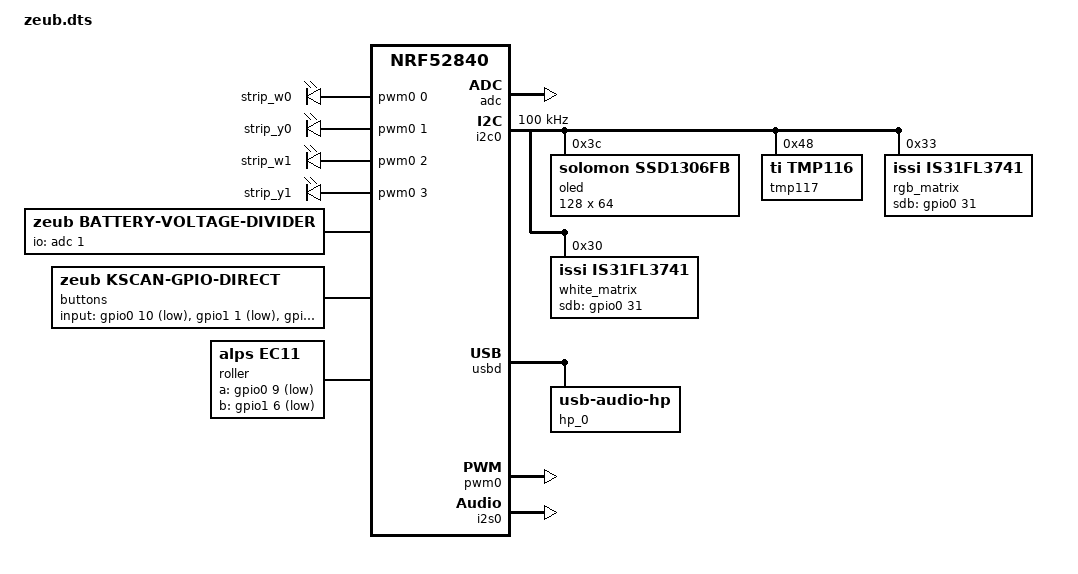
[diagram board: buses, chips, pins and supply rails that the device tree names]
/dts-v1/;
#include <nordic/nrf52840_qiaa.dtsi>

#include <dt-bindings/led/led.h>
#include <dt-bindings/zeub/is31fl3741_transform.h>
#include <dt-bindings/pwm/pwm.h>
#include "zeub-pinctrl.dtsi"

 / {
	chosen {
		zephyr,bt-mon-uart = &uart0;
		zephyr,bt-c2h-uart = &uart0;
		zephyr,sram = &sram0;
		zephyr,flash = &flash0;
		zephyr,code-partition = &flash_code_raw;
        zephyr,console = &cdc_dev;
        zephyr,display = &oled;
	};

    led_strip: led_strip {
        compatible = "pwm-leds";
        strip_w0 {
            pwms = <&pwm0 0 100000 0>;
        };
        strip_y0 {
            pwms = <&pwm0 1 100000 0>;
        };
        strip_w1 {
            pwms = <&pwm0 2 100000 0>;
        };
        strip_y1 {
            pwms = <&pwm0 3 100000 0>;
        };
    };

    bat {
        compatible = "zeub,battery-voltage-divider";
        io-channels = <&adc 1>;
        output-ohms = <1>;
        full-ohms = <(1 + 1)>;
    };

    buttons: kscan {
        compatible = "zeub,kscan-gpio-direct";
        status = "okay";
        input-gpios
			= <&gpio0 10 (GPIO_PULL_UP | GPIO_ACTIVE_LOW)>      // Encoder push button
			, <&gpio1  1 (GPIO_PULL_UP | GPIO_ACTIVE_LOW)>      // 5 way select up/A
			, <&gpio1 10 (GPIO_PULL_UP | GPIO_ACTIVE_LOW)>      // 5 way select down/D
			, <&gpio1  4 (GPIO_PULL_UP | GPIO_ACTIVE_LOW)>      // 5 way select left/C
			, <&gpio1 13 (GPIO_PULL_UP | GPIO_ACTIVE_LOW)>      // 5 way select right/B
			, <&gpio1  2 (GPIO_PULL_UP | GPIO_ACTIVE_LOW)>      // 5 way select center/E
            ;
    };

	roller: roller {
		compatible = "alps,ec11";
		status = "okay";
		a-gpios = <&gpio0 9 (GPIO_PULL_UP | GPIO_ACTIVE_LOW)>;
		b-gpios = <&gpio1 6 (GPIO_PULL_UP | GPIO_ACTIVE_LOW)>;
		resolution = <4>;
	};
};

&adc {
	status = "okay";
};

&gpiote {
	status = "okay";
};

&gpio0 {
	status = "okay";
};

&gpio1 {
	status = "okay";
};

/* &spi0 { */
/*     compatible = "nordic,nrf-spim"; */
/*     /1* status = "okay"; *1/ */
/*     sck-pin = <19>; */
/*     mosi-pin = <21>; */
/*     miso-pin = <23>; */
/* }; */

&i2c0 {
    compatible = "nordic,nrf-twi";
    status = "okay";
    pinctrl-0 = <&i2c0_def>;
    pinctrl-names = "default";
    clock-frequency = <I2C_BITRATE_STANDARD>;
    oled: ssd1306@3c {
        compatible = "solomon,ssd1306fb";
        status = "okay";
        reg = <0x3c>;
        width = <128>;
        height = <64>;
        segment-offset = <0>;
        page-offset = <0>;
        display-offset = <0>;
        multiplex-ratio = <63>;
        com-invdir;
        segment-remap;
        prechargep = <0x22>;
    };

    tmp117: tmp117@48 {
        compatible = "ti,tmp116";
        status = "okay";
        reg = <0x48>;
    };

	rgb_matrix: is31fl3741@33 {
		compatible = "issi,is31fl3741";
        status = "okay";
		reg = <0x33>;
		r-ext = <10>;
		led-max-current = <1>;
		sdb-gpios = <&gpio0 31 (GPIO_ACTIVE_HIGH | GPIO_PULL_DOWN)>;
		chain-length = <192>;
        red-scaling = <255>;
        green-scaling = <180>;
        blue-scaling = <200>;
        gamma = <0 1 2 3 4 5 6 7 8 9 10 11 12 13 14 15 16 17 18 19 20 21 22 23 24 25 26 27 28 29 30 31 32 33 34 35 36 37 38 39 40 41 42 43 44 45 46 47 48 49 50 51 52 53 54 55 56 57 58 59 60 61 62 63 64 65 66 67 68 69 70 71 72 73 74 75 76 77 78 79 80 81 82 83 84 85 86 87 88 89 90 91 92 93 94 95 96 97 98 99 100 101 102 103 104 105 106 107 108 109 110 111 112 113 114 115 116 117 118 119 120 121 122 123 124 125 126 127 128 129 130 131 132 133 134 135 136 137 138 139 140 141 142 143 144 145 146 147 148 149 150 151 152 153 154 155 156 157 158 159 160 161 162 163 164 165 166 167 168 169 170 171 172 173 174 175 176 177 178 179 180 181 182 183 184 185 186 187 188 189 190 191 192 193 194 195 196 197 198 199 200 201 202 203 204 205 206 207 208 209 210 211 212 213 214 215 216 217 218 219 220 221 222 223 224 225 226 227 228 229 230 231 232 233 234 235 236 237 238 239 240 241 242 243 244 245 246 247 248 249 250 251 252 253 254 255>;

#define PIX(c, r, g, b) RGB(SW(c), CS(r), CS(g), CS(b))
		map = <
            PIX(8, 17, 16, 15) PIX(8, 14, 13, 12) PIX(8, 11, 10, 9)  PIX(8, 8, 7, 6)
            PIX(8, 39, 38, 37) PIX(8, 36, 35, 34) PIX(8, 33, 32, 31) PIX(8, 30, 29, 28)
            PIX(7, 17, 16, 15) PIX(7, 14, 13, 12) PIX(7, 11, 10, 9)  PIX(7, 8, 7, 6)
            PIX(7, 39, 38, 37) PIX(7, 36, 35, 34) PIX(7, 33, 32, 31) PIX(7, 30, 29, 28)
            PIX(6, 17, 16, 15) PIX(6, 14, 13, 12) PIX(6, 11, 10, 9)  PIX(6, 8, 7, 6)
            PIX(6, 39, 38, 37) PIX(6, 36, 35, 34) PIX(6, 33, 32, 31) PIX(6, 30, 29, 28)
            PIX(5, 17, 16, 15) PIX(5, 14, 13, 12) PIX(5, 11, 10, 9)  PIX(5, 8, 7, 6)
            PIX(5, 39, 38, 37) PIX(5, 36, 35, 34) PIX(5, 33, 32, 31) PIX(5, 30, 29, 28)
            PIX(4, 17, 16, 15) PIX(4, 14, 13, 12) PIX(4, 11, 10, 9)  PIX(4, 8, 7, 6)
            PIX(4, 39, 38, 37) PIX(4, 36, 35, 34) PIX(4, 33, 32, 31) PIX(4, 30, 29, 28)
            PIX(3, 17, 16, 15) PIX(3, 14, 13, 12) PIX(3, 11, 10, 9)  PIX(3, 8, 7, 6)
            PIX(3, 39, 38, 37) PIX(3, 36, 35, 34) PIX(3, 33, 32, 31) PIX(3, 30, 29, 28)
            PIX(2, 17, 16, 15) PIX(2, 14, 13, 12) PIX(2, 11, 10, 9)  PIX(2, 8, 7, 6)
            PIX(2, 39, 38, 37) PIX(2, 36, 35, 34) PIX(2, 33, 32, 31) PIX(2, 30, 29, 28)
            PIX(1, 17, 16, 15) PIX(1, 14, 13, 12) PIX(1, 11, 10, 9)  PIX(1, 8, 7, 6)
            PIX(1, 39, 38, 37) PIX(1, 36, 35, 34) PIX(1, 33, 32, 31) PIX(1, 30, 29, 28)
            >;
    };

	white_matrix: is31fl3741@30 {
		compatible = "issi,is31fl3741";
        status = "okay";
		reg = <0x30>;
		r-ext = <10>;
		led-max-current = <1>;
		sdb-gpios = <&gpio0 31 (GPIO_ACTIVE_HIGH | GPIO_PULL_DOWN)>;
		chain-length = <256>;
        red-scaling = <255>;
        green-scaling = <255>;
        blue-scaling = <255>;
        gamma = <0 1 2 3 4 5 6 7 8 9 10 11 12 13 14 15 16 17 18 19 20 21 22 23 24 25 26 27 28 29 30 31 32 33 34 35 36 37 38 39 40 41 42 43 44 45 46 47 48 49 50 51 52 53 54 55 56 57 58 59 60 61 62 63 64 65 66 67 68 69 70 71 72 73 74 75 76 77 78 79 80 81 82 83 84 85 86 87 88 89 90 91 92 93 94 95 96 97 98 99 100 101 102 103 104 105 106 107 108 109 110 111 112 113 114 115 116 117 118 119 120 121 122 123 124 125 126 127 128 129 130 131 132 133 134 135 136 137 138 139 140 141 142 143 144 145 146 147 148 149 150 151 152 153 154 155 156 157 158 159 160 161 162 163 164 165 166 167 168 169 170 171 172 173 174 175 176 177 178 179 180 181 182 183 184 185 186 187 188 189 190 191 192 193 194 195 196 197 198 199 200 201 202 203 204 205 206 207 208 209 210 211 212 213 214 215 216 217 218 219 220 221 222 223 224 225 226 227 228 229 230 231 232 233 234 235 236 237 238 239 240 241 242 243 244 245 246 247 248 249 250 251 252 253 254 255>;

#define PIX16(r, c1, c2, c3, c4, c5, c6, c7, c8 , c9, c10, c11, c12, c13, c14, c15, c16) \
        PIXEL(SW(r) + CS(c1)) PIXEL(SW(r) + CS(c2)) PIXEL(SW(r) + CS(c3)) PIXEL(SW(r) + CS(c4)) \
        PIXEL(SW(r) + CS(c5)) PIXEL(SW(r) + CS(c6)) PIXEL(SW(r) + CS(c7)) PIXEL(SW(r) + CS(c8)) \
        PIXEL(SW(r) + CS(c9)) PIXEL(SW(r) + CS(c10)) PIXEL(SW(r) + CS(c11)) PIXEL(SW(r) + CS(c12)) \
        PIXEL(SW(r) + CS(c13)) PIXEL(SW(r) + CS(c14)) PIXEL(SW(r) + CS(c15)) PIXEL(SW(r) + CS(c16))
		map = <
            PIX16(1, 16, 15, 14, 13, 12, 11, 10, 9, 8, 7, 6, 5, 4, 3, 2, 1)
            PIX16(1, 39, 38, 37, 36, 35, 34, 33, 32, 31, 30, 29, 28, 27, 26, 25, 24)
            PIX16(2, 16, 15, 14, 13, 12, 11, 10, 9, 8, 7, 6, 5, 4, 3, 2, 1)
            PIX16(2, 39, 38, 37, 36, 35, 34, 33, 32, 31, 30, 29, 28, 27, 26, 25, 24)
            PIX16(3, 16, 15, 14, 13, 12, 11, 10, 9, 8, 7, 6, 5, 4, 3, 2, 1)
            PIX16(3, 39, 38, 37, 36, 35, 34, 33, 32, 31, 30, 29, 28, 27, 26, 25, 24)
            PIX16(4, 16, 15, 14, 13, 12, 11, 10, 9, 8, 7, 6, 5, 4, 3, 2, 1)
            PIX16(4, 39, 38, 37, 36, 35, 34, 33, 32, 31, 30, 29, 28, 27, 26, 25, 24)
            PIX16(5, 16, 15, 14, 13, 12, 11, 10, 9, 8, 7, 6, 5, 4, 3, 2, 1)
            PIX16(5, 39, 38, 37, 36, 35, 34, 33, 32, 31, 30, 29, 28, 27, 26, 25, 24)
            PIX16(6, 16, 15, 14, 13, 12, 11, 10, 9, 8, 7, 6, 5, 4, 3, 2, 1)
            PIX16(6, 39, 38, 37, 36, 35, 34, 33, 32, 31, 30, 29, 28, 27, 26, 25, 24)
            PIX16(7, 16, 15, 14, 13, 12, 11, 10, 9, 8, 7, 6, 5, 4, 3, 2, 1)
            PIX16(7, 39, 38, 37, 36, 35, 34, 33, 32, 31, 30, 29, 28, 27, 26, 25, 24)
            PIX16(8, 16, 15, 14, 13, 12, 11, 10, 9, 8, 7, 6, 5, 4, 3, 2, 1)
            PIX16(8, 39, 38, 37, 36, 35, 34, 33, 32, 31, 30, 29, 28, 27, 26, 25, 24)
            >;
    };
};

&spi1 { status = "disabled"; };

&flash0 {
	/*
	 * For more information, see:
	 * http://docs.zephyrproject.org/latest/devices/dts/flash_partitions.html
	 */
	my-partitions {
		compatible = "fixed-partitions";
		#address-cells = <1>;
		#size-cells = <1>;

		flash_sd: partition_sd@0 {
			label = "softdevice";
			reg = <0x00000000 0x00026000>;
		};
		flash_mbr: partition@0 {
			label = "mbr";
			reg = <0x00000000 0x00001000>;
		};
		flash_code_soft: partition@26000 {
			label = "code_partition_softdevice";
			reg = <0x00026000 0x000c6000>;
		};
		flash_code: partition@1000 {
			label = "code_partition";
			reg = <0x00001000 0x000eb000>;
		};
		flash_code_raw: partition_raw@0 {
			label = "raw_code_partition";
			reg = <0x00000000 0x000ec000>;
		};

		/*
		 * The flash starting at 0x000ec000 and ending at
		 * 0x000f3fff is reserved for use by the application.
		 */

		/*
		 * Storage partition will be used by FCB/LittleFS/NVS
		 * if enabled.
		 */
		storage_partition: partition@ec000 {
			label = "storage";
			reg = <0x000ec000 0x00008000>;
		};

		flash_boot: partition@f4000 {
			label = "adafruit_boot";
			reg = <0x000f4000 0x0000c000>;
		};
	};
};

zephyr_udc0: &usbd {
	compatible = "nordic,nrf-usbd";
	status = "okay";

	cdc_dev: cdc_acm_uart0 {
		compatible = "zephyr,cdc-acm-uart";
		label = "CDC_ACM_0";
	};

	hp_0 {
		compatible = "usb-audio-hp";
		feature-mute;
		channel-l;
		channel-r;
	};
};

&pwm0 {
    status = "okay";
    pinctrl-0 = <&pwm0_def>;
    pinctrl-names = "default";
};

i2s_tx: &i2s0 {
	status = "okay";
	pinctrl-0 = <&i2s0_default_alt>;
	pinctrl-names = "default";
};
